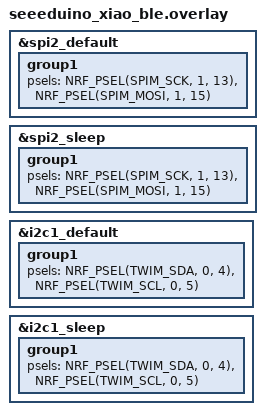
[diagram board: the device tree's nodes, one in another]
&spi2_default {
	group1 {
		psels = <NRF_PSEL(SPIM_SCK, 1, 13)>,
			    <NRF_PSEL(SPIM_MOSI, 1, 15)>;
	};
};

&spi2_sleep {
	group1 {
		psels = <NRF_PSEL(SPIM_SCK, 1, 13)>,
			    <NRF_PSEL(SPIM_MOSI, 1, 15)>;
	};
};

&i2c1_default {
	group1 {
        psels = <NRF_PSEL(TWIM_SDA, 0, 4)>,
                <NRF_PSEL(TWIM_SCL, 0, 5)>;
	};
};

&i2c1_sleep {
	group1 {
        psels = <NRF_PSEL(TWIM_SDA, 0, 4)>,
                <NRF_PSEL(TWIM_SCL, 0, 5)>;
	};
};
